# M451_v1 register map
File version: 1.0
Registers are 32-bit, read-write, reset 0x0 unless marked. A register's access mark holds for its fields unless they carry their own. Offsets are from the block's base; [hi:lo] are bit positions; {n}, {i} and the like mark numbered series.

## SYS — SYS Register Map
Base 0x40000000
0x00 SYS_PDID ro reset not defined — Part Device Identification Number Register
  [31:0] PDID — Part Device Identification Number (Read Only). This register reflects device part number code. Software can read this register to identify which device is used.
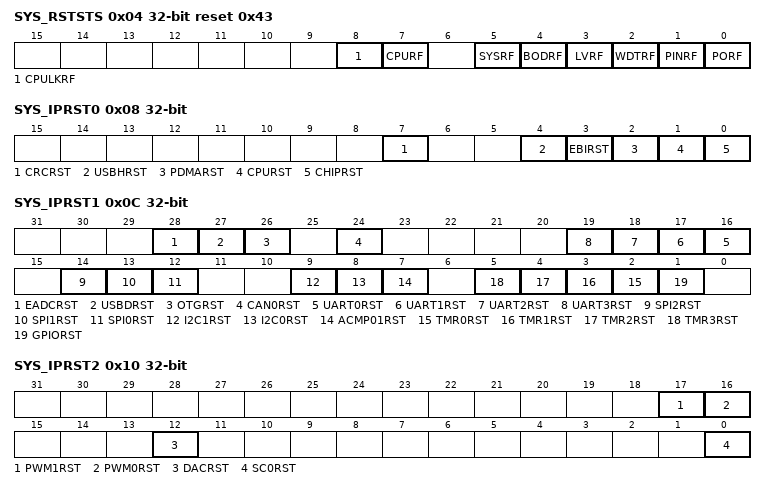
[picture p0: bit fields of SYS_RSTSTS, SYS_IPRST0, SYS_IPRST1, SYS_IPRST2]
0x04 SYS_RSTSTS reset 0x43 — System Reset Status Register
  [8] CPULKRF — the CPULK Reset Flag Is Set by Hardware If Cortex-m4 Lockup Happened (M45xD/M45xC Only). Note: Write 1 to clear this bit to 0.
    0=No reset from CPU lockup happened; 1=The Cortex-M4 lockup happened and chip is reset
  [7] CPURF — CPU Reset Flag. The CPU reset flag is set by hardware if software writes CPURST (SYS_IPRST0[1]) 1 to reset Cortex-M4 Core and Flash Memory Controller (FMC). Note: Write 1 to clear this bit to 0.
    0=No reset from CPU; 1=The Cortex-M4 Core and FMC are reset by software setting CPURST to 1
  [5] SYSRF — System Reset Flag. The system reset flag is set by the 'Reset Signal' from the Cortex-M4 Core to indicate the previous reset source. Note: Write 1 to clear this bit to 0.
    0=No reset from Cortex-M4; 1=The Cortex-M4 had issued the reset signal to reset the system by writing 1 to the bit SYSRESETREQ(AIRCR[2], Application Interrupt and Reset Control Register, address = 0xE000ED0C) in system control registers of Cortex-M4 core
  [4] BODRF — BOD Reset Flag. The BOD reset flag is set by the 'Reset Signal' from the Brown-Out Detector to indicate the previous reset source. Note: Write 1 to clear this bit to 0.
    0=No reset from BOD; 1=The BOD had issued the reset signal to reset the system
  [3] LVRF — LVR Reset Flag. The LVR reset flag is set by the 'Reset Signal' from the Low Voltage Reset Controller to indicate the previous reset source. Note: Write 1 to clear this bit to 0.
    0=No reset from LVR; 1=LVR controller had issued the reset signal to reset the system
  [2] WDTRF — WDT Reset Flag. The WDT reset flag is set by the 'Reset Signal' from the Watchdog Timer or Window Watchdog Timer to indicate the previous reset source. Note1: Write 1 to clear this bit to 0. Note2: Watchdog Timer register RSTF(WDT_CTL[2]) bit is set if the system has been reset by WDT time-out reset. Window Watchdog Timer register WWDTRF(WWDT_STATUS[1]) bit is set if the system has been reset by WWDT time-out reset.
    0=No reset from watchdog timer or window watchdog timer; 1=The watchdog timer or window watchdog timer had issued the reset signal to reset the system
  [1] PINRF — NRESET Pin Reset Flag. The nRESET pin reset flag is set by the 'Reset Signal' from the nRESET Pin to indicate the previous reset source. Note: Write 1 to clear this bit to 0.
    0=No reset from nRESET pin; 1=Pin nRESET had issued the reset signal to reset the system
  [0] PORF — POR Reset Flag. The POR reset flag is set by the 'Reset Signal' from the Power-on Reset (POR) Controller or bit CHIPRST (SYS_IPRST0[0]) to indicate the previous reset source. Note: Write 1 to clear this bit to 0.
    0=No reset from POR or CHIPRST; 1=Power-on Reset (POR) or CHIPRST had issued the reset signal to reset the system
0x08 SYS_IPRST0 — Peripheral Reset Control Register 0
  [7] CRCRST — CRC Calculation Controller Reset (Write Protect). Set this bit to 1 will generate a reset signal to the CRC calculation controller. User needs to set this bit to 0 to release from the reset state. Note: This bit is write protected. Refer to the SYS_REGLCTL register.
    0=CRC calculation controller normal operation; 1=CRC calculation controller reset
  [4] USBHRST — USBH Controller Reset (Write Protect) (M45xG/M45xE Only). Set this bit to 1 will generate a reset signal to the USB host controller. User needs to set this bit to 0 to release from the reset state. Note: This bit is write protected. Refer to the SYS_REGLCTL register.
    0=USBH controller normal operation; 1=USBH controller reset
  [3] EBIRST — EBI Controller Reset (Write Protect). Set this bit to 1 will generate a reset signal to the EBI. User needs to set this bit to 0 to release from the reset state. Note: This bit is write protected. Refer to the SYS_REGLCTL register.
    0=EBI controller normal operation; 1=EBI controller reset
  [2] PDMARST — PDMA Controller Reset (Write Protect). Setting this bit to 1 will generate a reset signal to the PDMA. User needs to set this bit to 0 to release from reset state. Note: This bit is write protected. Refer to the SYS_REGLCTL register.
    0=PDMA controller normal operation; 1=PDMA controller reset
  [1] CPURST — Processor Core One-shot Reset (Write Protect). Setting this bit will only reset the processor core and Flash Memory Controller(FMC), and this bit will automatically return to 0 after the 2 clock cycles. Note: This bit is write protected. Refer to the SYS_REGLCTL register.
    0=Processor core normal operation; 1=Processor core one-shot reset
  [0] CHIPRST — Chip One-shot Reset (Write Protect). Setting this bit will reset the whole chip, including Processor core and all peripherals, and this bit will automatically return to 0 after the 2 clock cycles. The CHIPRST is same as the POR reset, all the chip controllers is reset and the chip setting from flash are also reload. About the difference between CHIPRST and SYSRESETREQ(AIRCR[2]), please refer to section 6.2.2. Note: This bit is write protected. Refer to the SYS_REGLCTL register.
    0=Chip normal operation; 1=Chip one-shot reset
0x0C SYS_IPRST1 — Peripheral Reset Control Register 1
  [28] EADCRST — EADC Controller Reset
    0=EADC controller normal operation; 1=EADC controller reset
  [27] USBDRST — USB Device Controller Reset
    0=USB device controller normal operation; 1=USB device controller reset
  [26] OTGRST — OTG Controller Reset (M45xG/M45xE Only)
    0=OTG controller normal operation; 1=OTG controller reset
  [24] CAN0RST — CAN0 Controller Reset
    0=CAN0 controller normal operation; 1=CAN0 controller reset
  [n+16] UART{n}RST (n=0..3) — UART{n} Controller Reset
    0=UART{n} controller normal operation; 1=UART{n} controller reset
  [14] SPI2RST — SPI2 Controller Reset (M45xG/M45xE Only)
    0=SPI2 controller normal operation; 1=SPI2 controller reset
  [13] SPI1RST — SPI1 Controller Reset
    0=SPI1 controller normal operation; 1=SPI1 controller reset
  [12] SPI0RST — SPI0 Controller Reset
    0=SPI0 controller normal operation; 1=SPI0 controller reset
  [9] I2C1RST — I2C1 Controller Reset
    0=I2C1 controller normal operation; 1=I2C1 controller reset
  [8] I2C0RST — I2C0 Controller Reset
    0=I2C0 controller normal operation; 1=I2C0 controller reset
  [7] ACMP01RST — Analog Comparator 0/1 Controller Reset
    0=Analog Comparator 0/1 controller normal operation; 1=Analog Comparator 0/1 controller reset
  [n+2] TMR{n}RST (n=0..3) — Timer{n} Controller Reset
    0=Timer{n} controller normal operation; 1=Timer{n} controller reset
  [1] GPIORST — GPIO Controller Reset
    0=GPIO controller normal operation; 1=GPIO controller reset
0x10 SYS_IPRST2 — Peripheral Reset Control Register 2
  [17] PWM1RST — PWM1 Controller Reset
    0=PWM1 controller normal operation; 1=PWM1 controller reset
  [16] PWM0RST — PWM0 Controller Reset
    0=PWM0 controller normal operation; 1=PWM0 controller reset
  [12] DACRST — DAC Controller Reset
    0=DAC controller normal operation; 1=DAC controller reset
  [0] SC0RST — SC0 Controller Reset
    0=SC0 controller normal operation; 1=SC0 controller reset
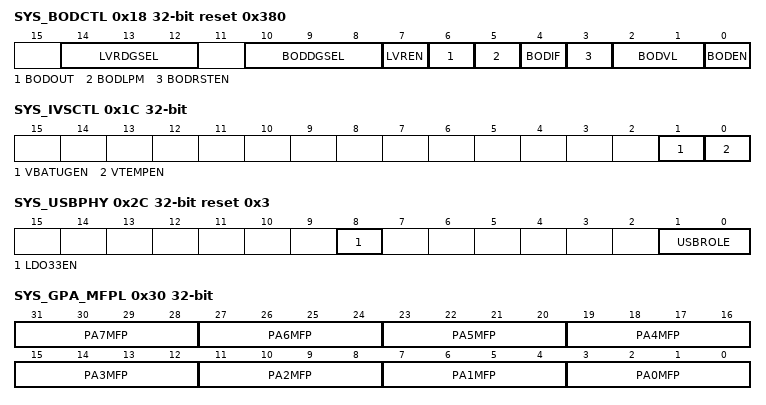
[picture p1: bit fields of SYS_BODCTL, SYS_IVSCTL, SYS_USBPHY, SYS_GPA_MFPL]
0x18 SYS_BODCTL reset 0x380 (reset mask 0xFFFFFFF0) — Brown-out Detector Control Register
  [14:12] LVRDGSEL — LVR Output De-glitch Time Select (Write Protect). Note: These bits are write protected. Refer to the SYS_REGLCTL register.
    0=Without de-glitch function; 1=4 system clock (HCLK); 2=8 system clock (HCLK); 3=16 system clock (HCLK); 4=32 system clock (HCLK); 5=64 system clock (HCLK); 6=128 system clock (HCLK); 7=256 system clock (HCLK)
  [10:8] BODDGSEL — Brown-out Detector Output De-glitch Time Select (Write Protect). Note: These bits are write protected. Refer to the SYS_REGLCTL register.
    0=BOD output is sampled by RC10K clock; 1=4 system clock (HCLK); 2=8 system clock (HCLK); 3=16 system clock (HCLK); 4=32 system clock (HCLK); 5=64 system clock (HCLK); 6=128 system clock (HCLK); 7=256 system clock (HCLK)
  [7] LVREN — Low Voltage Reset Enable Bit (Write Protect). The LVR function resets the chip when the input power voltage is lower than LVR circuit setting. LVR function is enabled by default. Note1: After enabling the bit, the LVR function will be active with 100us delay for LVR output stable (default). Note2: This bit is write protected. Refer to the SYS_REGLCTL register. Note3: LIRC must be enabled before enable LVR.
    0=Low Voltage Reset function Disabled; 1=Low Voltage Reset function Enabled
  [6] BODOUT — Brown-out Detector Output Status. It means the detected voltage is lower than BODVL setting. If the BODEN is 0, BOD function disabled , this bit always responds 0.
    0=Brown-out Detector output status is 0; 1=Brown-out Detector output status is 1
  [5] BODLPM — Brown-out Detector Low Power Mode (Write Protect). Note1: The BOD consumes about 100uA in normal mode, the low power mode can reduce the current to about 1/10 but slow the BOD response. Note2: This bit is write protected. Refer to the SYS_REGLCTL register.
    0=BOD operate in normal mode (default); 1=BOD Low Power mode Enabled
  [4] BODIF — Brown-out Detector Interrupt Flag. Note: Write 1 to clear this bit to 0.
    0=Brown-out Detector does not detect any voltage draft at VDD down through or up through the voltage of BODVL setting; 1=When Brown-out Detector detects the VDD is dropped down through the voltage of BODVL setting or the VDD is raised up through the voltage of BODVL setting, this bit is set to 1 and the brown-out interrupt is requested if brown-out interrupt is enabled
  [3] BODRSTEN — Brown-out Reset Enable Bit (Write Protect). The default value is set by flash controller user configuration register CBORST(CONFIG0[20]) bit . Note1: While the Brown-out Detector function is enabled (BODEN high) and BOD reset function is enabled (BODRSTEN high), BOD will assert a signal to reset chip when the detected voltage is lower than the threshold (BODOUT high). While the BOD function is enabled (BODEN high) and BOD interrupt function is enabled (BODRSTEN low), BOD will assert an interrupt if BODOUT is high. BOD interrupt will keep till to the BODEN set to 0. BOD interrupt can be blocked by disabling the NVIC BOD interrupt or disabling BOD function (set BODEN low). Note2: This bit is write protected. Refer to the SYS_REGLCTL register.
    0=Brown-out 'INTERRUPT' function Enabled; 1=Brown-out 'RESET' function Enabled
  [2:1] BODVL — Brown-out Detector Threshold Voltage Selection (Write Protect). The default value is set by flash controller user configuration register CBOV (CONFIG0 [22:21]). Note: This bit is write protected. Refer to the SYS_REGLCTL register.
    0=Brown-Out Detector threshold voltage is 2.2V; 1=Brown-Out Detector threshold voltage is 2.7V; 2=Brown-Out Detector threshold voltage is 3.7V; 3=Brown-Out Detector threshold voltage is 4.4V
  [0] BODEN — Brown-out Detector Enable Bit (Write Protect). The default value is set by flash controller user configuration register CBODEN (CONFIG0 [23]). Note1: This bit is write protected. Refer to the SYS_REGLCTL register. Note2: LIRC must be enabled before enable BOD.
    0=Brown-out Detector function Disabled; 1=Brown-out Detector function Enabled
0x1C SYS_IVSCTL — Internal Voltage Source Control Register
  [1] VBATUGEN — VBAT Unity Gain Buffer Enable Bit. This bit is used to enable/disable VBAT unity gain buffer function. Note: After this bit is set to 1, the value of VBAT unity gain buffer output voltage can be obtained from ADC conversion result
    0=VBAT unity gain buffer function Disabled (default); 1=VBAT unity gain buffer function Enabled
  [0] VTEMPEN — Temperature Sensor Enable Bit. This bit is used to enable/disable temperature sensor function. Note: After this bit is set to 1, the value of temperature sensor output can be obtained from ADC conversion result. Please refer to ADC function chapter for details.
    0=Temperature sensor function Disabled (default); 1=Temperature sensor function Enabled
0x24 SYS_PORCTL (reset mask 0xFFFF0000) — Power-On-reset Controller Register
  [15:0] POROFF — Power-on Reset Enable Bit (Write Protect). When powered on, the POR circuit generates a reset signal to reset the whole chip function, but noise on the power may cause the POR active again. User can disable internal POR circuit to avoid unpredictable noise to cause chip reset by writing 0x5AA5 to this field. The POR function will be active again when this field is set to another value or chip is reset by other reset source, including: nRESET, Watchdog, LVR reset, BOD reset, ICE reset command and the software-chip reset function. Note: This bit is write protected. Refer to the SYS_REGLCTL register.
0x28 SYS_VREFCTL — VREF Control Register
  [4:0] VREFCTL — VREF Control Bits (Write Protect). Note1: This bit is write protected. Refer to the SYS_REGLCTL register. Note2: Connecting a 1uF capacitor to AVSS will make internal reference voltage more stable.
    0=VREF is from external pin; 3=VREF is internal 2.56V; 7=VREF is internal 2.048V; 11=VREF is internal 3.072V; 15=VREF is internal 4.096V
0x2C SYS_USBPHY reset 0x3 — USB PHY Control Register (M45xG/M45xE Only)
  [8] LDO33EN — USB LDO33 Enable Bit (Write Protect) (M45xG/M45xE Only). Note: This bit is write protected. Refer to the SYS_REGLCTL register.
    0=USB LDO33 Disabled; 1=USB LDO33 Enabled
  [1:0] USBROLE — USB Role Option (Write Protect) (M45xG/M45xE Only). These two bits are used to select the role of USB. Note: This bit is write protected. Refer to the SYS_REGLCTL register.
    0=Standard USB Device mode; 1=Standard USB Host mode; 2=ID dependent mode; 3=On-The-Go device mode
0x30 SYS_GPA_MFPL — GPIOA Low Byte Multiple Function Control Register
  [31:28] PA7MFP — PA.7 Multi-function Pin Selection
  [27:24] PA6MFP — PA.6 Multi-function Pin Selection
  [23:20] PA5MFP — PA.5 Multi-function Pin Selection
  [19:16] PA4MFP — PA.4 Multi-function Pin Selection
  [15:12] PA3MFP — PA.3 Multi-function Pin Selection
  [11:8] PA2MFP — PA.2 Multi-function Pin Selection
  [7:4] PA1MFP — PA.1 Multi-function Pin Selection
  [3:0] PA0MFP — PA.0 Multi-function Pin Selection
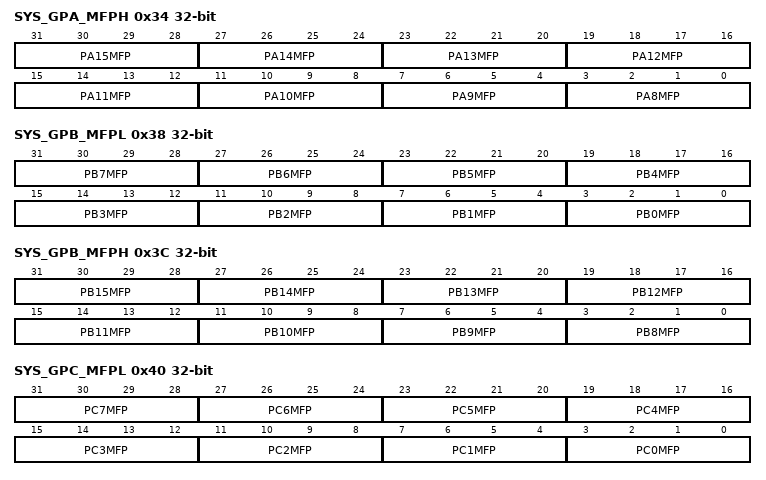
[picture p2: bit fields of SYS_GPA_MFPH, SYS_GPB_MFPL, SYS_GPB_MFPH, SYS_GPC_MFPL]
0x34 SYS_GPA_MFPH — GPIOA High Byte Multiple Function Control Register
  [31:28] PA15MFP — PA.15 Multi-function Pin Selection
  [27:24] PA14MFP — PA.14 Multi-function Pin Selection
  [23:20] PA13MFP — PA.13 Multi-function Pin Selection
  [19:16] PA12MFP — PA.12 Multi-function Pin Selection
  [15:12] PA11MFP — PA.11 Multi-function Pin Selection
  [11:8] PA10MFP — PA.10 Multi-function Pin Selection
  [7:4] PA9MFP — PA.9 Multi-function Pin Selection
  [3:0] PA8MFP — PA.8 Multi-function Pin Selection
0x38 SYS_GPB_MFPL — GPIOB Low Byte Multiple Function Control Register
  [31:28] PB7MFP — PB.7 Multi-function Pin Selection
  [27:24] PB6MFP — PB.6 Multi-function Pin Selection
  [23:20] PB5MFP — PB.5 Multi-function Pin Selection
  [19:16] PB4MFP — PB.4 Multi-function Pin Selection
  [15:12] PB3MFP — PB.3 Multi-function Pin Selection
  [11:8] PB2MFP — PB.2 Multi-function Pin Selection
  [7:4] PB1MFP — PB.1 Multi-function Pin Selection
  [3:0] PB0MFP — PB.0 Multi-function Pin Selection
0x3C SYS_GPB_MFPH — GPIOB High Byte Multiple Function Control Register
  [31:28] PB15MFP — PB.15 Multi-function Pin Selection
  [27:24] PB14MFP — PB.14 Multi-function Pin Selection
  [23:20] PB13MFP — PB.13 Multi-function Pin Selection
  [19:16] PB12MFP — PB.12 Multi-function Pin Selection
  [15:12] PB11MFP — PB.11 Multi-function Pin Selection
  [11:8] PB10MFP — PB.10 Multi-function Pin Selection
  [7:4] PB9MFP — PB.9 Multi-function Pin Selection
  [3:0] PB8MFP — PB.8 Multi-function Pin Selection
0x40 SYS_GPC_MFPL — GPIOC Low Byte Multiple Function Control Register
  [31:28] PC7MFP — PC.7 Multi-function Pin Selection
  [27:24] PC6MFP — PC.6 Multi-function Pin Selection
  [23:20] PC5MFP — PC.5 Multi-function Pin Selection
  [19:16] PC4MFP — PC.4 Multi-function Pin Selection
  [15:12] PC3MFP — PC.3 Multi-function Pin Selection
  [11:8] PC2MFP — PC.2 Multi-function Pin Selection
  [7:4] PC1MFP — PC.1 Multi-function Pin Selection
  [3:0] PC0MFP — PC.0 Multi-function Pin Selection
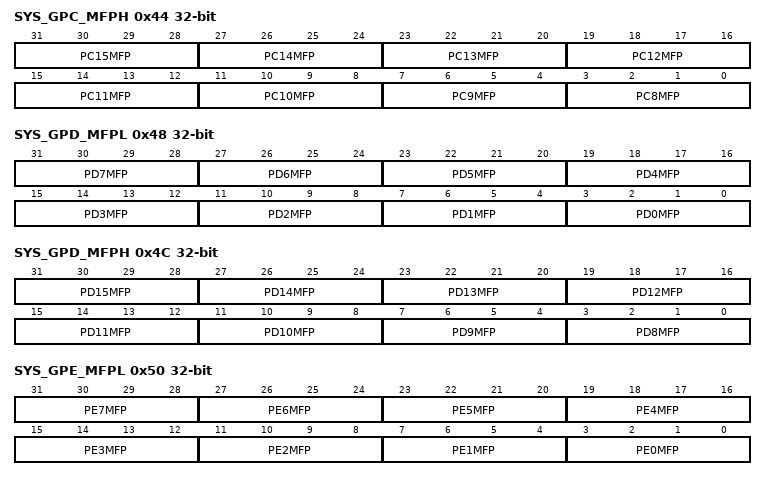
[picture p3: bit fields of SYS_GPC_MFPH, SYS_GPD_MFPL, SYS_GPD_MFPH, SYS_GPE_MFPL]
0x44 SYS_GPC_MFPH — GPIOC High Byte Multiple Function Control Register
  [31:28] PC15MFP — PC.15 Multi-function Pin Selection
  [27:24] PC14MFP — PC.14 Multi-function Pin Selection
  [23:20] PC13MFP — PC.13 Multi-function Pin Selection
  [19:16] PC12MFP — PC.12 Multi-function Pin Selection
  [15:12] PC11MFP — PC.11 Multi-function Pin Selection
  [11:8] PC10MFP — PC.10 Multi-function Pin Selection
  [7:4] PC9MFP — PC.9 Multi-function Pin Selection
  [3:0] PC8MFP — PC.8 Multi-function Pin Selection
0x48 SYS_GPD_MFPL — GPIOD Low Byte Multiple Function Control Register
  [31:28] PD7MFP — PD.7 Multi-function Pin Selection
  [27:24] PD6MFP — PD.6 Multi-function Pin Selection
  [23:20] PD5MFP — PD.5 Multi-function Pin Selection
  [19:16] PD4MFP — PD.4 Multi-function Pin Selection
  [15:12] PD3MFP — PD.3 Multi-function Pin Selection
  [11:8] PD2MFP — PD.2 Multi-function Pin Selection
  [7:4] PD1MFP — PD.1 Multi-function Pin Selection
  [3:0] PD0MFP — PD.0 Multi-function Pin Selection
0x4C SYS_GPD_MFPH — GPIOD High Byte Multiple Function Control Register
  [31:28] PD15MFP — PD.15 Multi-function Pin Selection
  [27:24] PD14MFP — PD.14 Multi-function Pin Selection
  [23:20] PD13MFP — PD.13 Multi-function Pin Selection
  [19:16] PD12MFP — PD.12 Multi-function Pin Selection
  [15:12] PD11MFP — PD.11 Multi-function Pin Selection
  [11:8] PD10MFP — PD.10 Multi-function Pin Selection
  [7:4] PD9MFP — PD.9 Multi-function Pin Selection
  [3:0] PD8MFP — PD.8 Multi-function Pin Selection
0x50 SYS_GPE_MFPL — GPIOE Low Byte Multiple Function Control Register
  [31:28] PE7MFP — PE.7 Multi-function Pin Selection
  [27:24] PE6MFP — PE.6 Multi-function Pin Selection
  [23:20] PE5MFP — PE.5 Multi-function Pin Selection
  [19:16] PE4MFP — PE.4 Multi-function Pin Selection
  [15:12] PE3MFP — PE.3 Multi-function Pin Selection
  [11:8] PE2MFP — PE.2 Multi-function Pin Selection
  [7:4] PE1MFP — PE.1 Multi-function Pin Selection
  [3:0] PE0MFP — PE.0 Multi-function Pin Selection
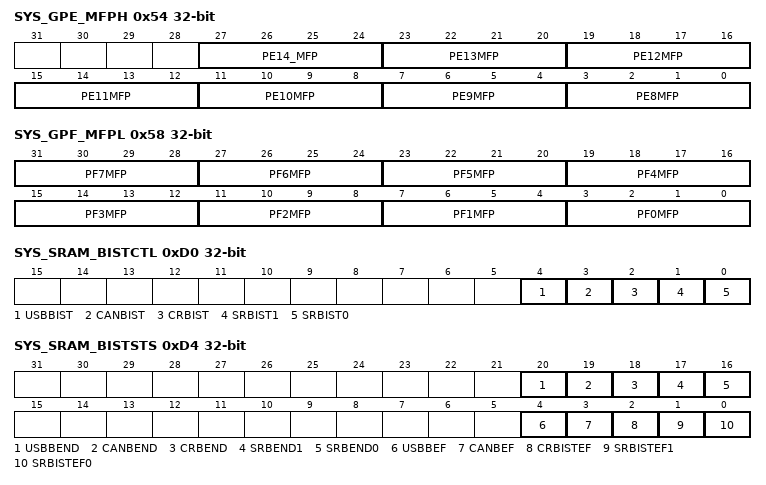
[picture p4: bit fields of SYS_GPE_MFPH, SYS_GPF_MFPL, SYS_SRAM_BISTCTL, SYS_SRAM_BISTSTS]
0x54 SYS_GPE_MFPH — GPIOE High Byte Multiple Function Control Register
  [27:24] PE14_MFP — PE.14 Multi-function Pin Selection
  [23:20] PE13MFP — PE.13 Multi-function Pin Selection
  [19:16] PE12MFP — PE.12 Multi-function Pin Selection
  [15:12] PE11MFP — PE.11 Multi-function Pin Selection
  [11:8] PE10MFP — PE.10 Multi-function Pin Selection
  [7:4] PE9MFP — PE.9 Multi-function Pin Selection
  [3:0] PE8MFP — PE.8 Multi-function Pin Selection
0x58 SYS_GPF_MFPL — GPIOF Low Byte Multiple Function Control Register
  [31:28] PF7MFP — PF.7 Multi-function Pin Selection
  [27:24] PF6MFP — PF.6 Multi-function Pin Selection
  [23:20] PF5MFP — PF.5 Multi-function Pin Selection
  [19:16] PF4MFP — PF.4 Multi-function Pin Selection
  [15:12] PF3MFP — PF.3 Multi-function Pin Selection
  [11:8] PF2MFP — PF.2 Multi-function Pin Selection
  [7:4] PF1MFP — PF.1 Multi-function Pin Selection
  [3:0] PF0MFP — PF.0 Multi-function Pin Selection
0xC0 SYS_SRAM_INTCTL — System SRAM Interrupt Enable Control Register
  [0] PERRIEN — SRAM Parity Check Error Interrupt Enable Bit
    0=SRAM parity check error interrupt Disabled; 1=SRAM parity check error interrupt Enabled
0xC4 SYS_SRAM_STATUS ro — System SRAM Parity Error Status Register
  [0] PERRIF — SRAM Parity Check Error Flag
    0=No System SRAM parity error; 1=System SRAM parity error occur
0xC8 SYS_SRAM_ERRADDR ro — System SRAM Parity Check Error Address Register
  [31:0] ERRADDR — System SRAM Parity Error Address. This register shows system SRAM parity error byte address.
0xD0 SYS_SRAM_BISTCTL — System SRAM BIST Test Control Register
  [4] USBBIST — USB BIST Enable Bit (Write Protect). This bit enables BIST test for USB RAM. Note: This bit is write protected. Refer to the SYS_REGLCTL register.
    0=system USB BIST Disabled; 1=system USB BIST Enabled
  [3] CANBIST — CAN BIST Enable Bit (Write Protect). This bit enables BIST test for CAN RAM. Note: This bit is write protected. Refer to the SYS_REGLCTL register.
    0=system CAN BIST Disabled; 1=system CAN BIST Enabled
  [2] CRBIST — CACHE BIST Enable Bit (Write Protect). This bit enables BIST test for CACHE RAM. Note: This bit is write protected. Refer to the SYS_REGLCTL register.
    0=system CACHE BIST Disabled; 1=system CACHE BIST Enabled
  [1] SRBIST1 — 2nd SRAM BIST Enable Bit (Write Protect). This bit enables BIST test for SRAM located in address 0x2000_4000 ~0x2000_7FFF. Note: This bit is write protected. Refer to the SYS_REGLCTL register.
    0=system SRAM BIST Disabled; 1=system SRAM BIST Enabled
  [0] SRBIST0 — 1st SRAM BIST Enable Bit (Write Protect). This bit enables BIST test for SRAM located in address 0x2000_0000 ~0x2000_3FFF. Note: This bit is write protected. Refer to the SYS_REGLCTL register.
    0=system SRAM BIST Disabled; 1=system SRAM BIST Enabled
0xD4 SYS_SRAM_BISTSTS ro (reset mask 0xFF00FF00) — System SRAM BIST Test Status Register
  [20] USBBEND — USB SRAM BIST Test Finish
    0=USB SRAM BIST is active; 1=USB SRAM BIST test finish
  [19] CANBEND — CAN SRAM BIST Test Finish
    0=CAN SRAM BIST is active; 1=CAN SRAM BIST test finish
  [18] CRBEND — CACHE SRAM BIST Test Finish
    0=System CACHE RAM BIST is active; 1=System CACHE RAM BIST test finish
  [17] SRBEND1 — 2nd SRAM BIST Test Finish
    0=2nd system SRAM BIST is active; 1=2nd system SRAM BIST finish
  [16] SRBEND0 — 1st SRAM BIST Test Finish
    0=1st system SRAM BIST active; 1=1st system SRAM BIST finish
  [4] USBBEF — USB SRAM BIST Fail Flag
    0=USB SRAM BIST test pass; 1=USB SRAM BIST test fail
  [3] CANBEF — CAN SRAM BIST Fail Flag
    0=CAN SRAM BIST test pass; 1=CAN SRAM BIST test fail
  [2] CRBISTEF — CACHE SRAM BIST Fail Flag
    0=System CACHE RAM BIST test pass; 1=System CACHE RAM BIST test fail
  [1] SRBISTEF1 — 2nd System SRAM BIST Fail Flag
    0=2nd system SRAM BIST test pass; 1=2nd system SRAM BIST test fail
  [0] SRBISTEF0 — 1st System SRAM BIST Fail Flag
    0=1st system SRAM BIST test pass; 1=1st system SRAM BIST test fail
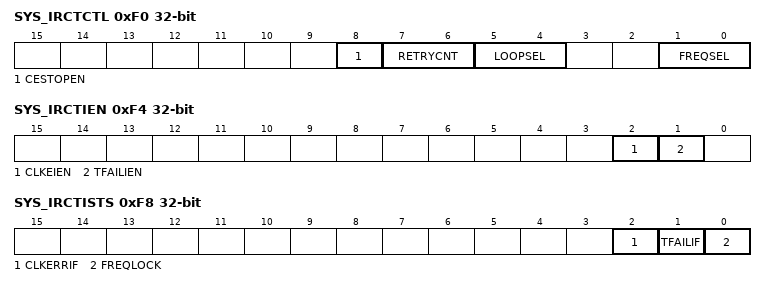
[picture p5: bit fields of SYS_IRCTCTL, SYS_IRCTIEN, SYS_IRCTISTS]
0xF0 SYS_IRCTCTL — HIRC Trim Control Register
  [8] CESTOPEN — Clock Error Stop Enable Bit
    0=The trim operation is keep going if clock is inaccuracy; 1=The trim operation is stopped if clock is inaccuracy
  [7:6] RETRYCNT — Trim Value Update Limitation Count. This field defines that how many times the auto trim circuit will try to update the HIRC trim value before the frequency of HIRC locked. Once the HIRC locked, the internal trim value update counter will be reset. If the trim value update counter reached this limitation value and frequency of HIRC still doesn't lock, the auto trim operation will be disabled and FREQSEL will be cleared to 00.
    0=Trim retry count limitation is 64 loops; 1=Trim retry count limitation is 128 loops; 2=Trim retry count limitation is 256 loops; 3=Trim retry count limitation is 512 loops
  [5:4] LOOPSEL — Trim Calculation Loop Selection. This field defines that trim value calculation is based on how many 32.768 kHz clock. Note: For example, if LOOPSEL is set as 00, auto trim circuit will calculate trim value based on the average frequency difference in 4 32.768 kHz clock.
    0=Trim value calculation is based on average difference in 4 32.768 kHz clock; 1=Trim value calculation is based on average difference in 8 32.768 kHz clock; 2=Trim value calculation is based on average difference in 16 32.768 kHz clock; 3=Trim value calculation is based on average difference in 32 32.768 kHz clock
  [1:0] FREQSEL — Trim Frequency Selection. This field indicates the target frequency of 22.1184 MHz internal high speed RC oscillator (HIRC) auto trim. During auto trim operation, if clock error detected with CESTOPEN is set to 1 or trim retry limitation count reached, this field will be cleared to 00 automatically. Note: HIRC auto trim cannot work normally at power down mode. These bits must be cleared before entering power down mode.
    0=Disable HIRC auto trim function; 1=Enable HIRC auto trim function and trim HIRC to 22.1184 MHz
0xF4 SYS_IRCTIEN — HIRC Trim Interrupt Enable Register
  [2] CLKEIEN — Clock Error Interrupt Enable Bit. This bit controls if CPU would get an interrupt while clock is inaccuracy during auto trim operation. If this bit is set to1, and CLKERRIF(SYS_IRCTSTS[2]) is set during auto trim operation, an interrupt will be triggered to notify the clock frequency is inaccuracy.
    0=Disable CLKERRIF(SYS_IRCTSTS[2]) status to trigger an interrupt to CPU; 1=Enable CLKERRIF(SYS_IRCTSTS[2]) status to trigger an interrupt to CPU
  [1] TFAILIEN — Trim Failure Interrupt Enable Bit. This bit controls if an interrupt will be triggered while HIRC trim value update limitation count reached and HIRC frequency still not locked on target frequency set by FREQSEL(SYS_IRCTCTL[1:0]). If this bit is high and TFAILIF(SYS_IRCTSTS[1]) is set during auto trim operation, an interrupt will be triggered to notify that HIRC trim value update limitation count was reached.
    0=Disable TFAILIF(SYS_IRCTSTS[1]) status to trigger an interrupt to CPU; 1=Enable TFAILIF(SYS_IRCTSTS[1]) status to trigger an interrupt to CPU
0xF8 SYS_IRCTISTS — HIRC Trim Interrupt Status Register
  [2] CLKERRIF — Clock Error Interrupt Status. When the frequency of 32.768 kHz external low speed crystal oscillator (LXT) or 22.1184 MHz internal high speed RC oscillator (HIRC) is shift larger to unreasonable value, this bit will be set and to be an indicate that clock frequency is inaccuracy. Once this bit is set to 1, the auto trim operation stopped and FREQSEL(SYS_IRCTCL[1:0]) will be cleared to 00 by hardware automatically if CESTOPEN(SYS_IRCTCTL[8]) is set to 1. If this bit is set and CLKEIEN(SYS_IRCTIEN[2]) is high, an interrupt will be triggered to notify the clock frequency is inaccuracy. Write 1 to clear this to 0.
    0=Clock frequency is accuracy; 1=Clock frequency is inaccuracy
  [1] TFAILIF — Trim Failure Interrupt Status. This bit indicates that HIRC trim value update limitation count reached and the HIRC clock frequency still doesn't be locked. Once this bit is set, the auto trim operation stopped and FREQSEL(SYS_iRCTCTL[1:0]) will be cleared to 00 by hardware automatically. If this bit is set and TFAILIEN(SYS_IRCTIEN[1]) is high, an interrupt will be triggered to notify that HIRC trim value update limitation count was reached. Write 1 to clear this to 0.
    0=Trim value update limitation count does not reach; 1=Trim value update limitation count reached and HIRC frequency still not locked
  [0] FREQLOCK — HIRC Frequency Lock Status. This bit indicates the HIRC frequency is locked. This is a status bit and doesn't trigger any interrupt.
    0=The internal high-speed oscillator frequency doesn't lock at 22.1184 MHz yet; 1=The internal high-speed oscillator frequency locked at 22.1184 MHz
0x100 SYS_REGLCTL — Register Lock Control Register
  [7:0] REGLCTL — Register Lock Control Code (Write Only). Some registers have write-protection function. Writing these registers have to disable the protected function by writing the sequence value '59h', '16h', '88h' to this field. After this sequence is completed, the REGLCTL bit will be set to 1 and write-protection registers can be normal write. Register Lock Control Disable Index (Read Only). The Protected registers are: SYS_IPRST0: address 0x4000_0008. SYS_BODCTL: address 0x4000_0018. SYS_PORCTL: address 0x4000_0024. SYS_VREFCTL: address 0x4000_0028. SYS_USBPHY: address 0x4000_002C. CLK_PWRCTL: address 0x4000_0200 (bit[6] is not protected for power-down wake-up interrupt clear). SYS_SRAM_BISTCTL: address 0x4000_00D0. CLK_APBCLK0 [0]: address 0x4000_0208 (bit[0] is watchdog clock enable). CLK_CLKSEL0: address 0x4000_0210 (for HCLK and CPU STCLK clock source select). CLK_CLKSEL1 [1:0]: address 0x4000_0214 (for watchdog clock source select). CLK_CLKSEL1 [31:30]: address 0x4000_0214 (for window watchdog clock source select). CLK_CLKDSTS: address 0x4000_0274. NMIEN: address 0x4000_0300. FMC_ISPCTL: address 0x4000_C000 (Flash ISP Control register). FMC_ISPTRG: address 0x4000_C010 (ISP Trigger Control register). FMC_ISPSTS: address 0x4000_C040. WDT_CTL: address 0x4004_0000. FMC_FTCTL: address 0x4000_5018. SYS_AHBMCTL: address 0x40000400. CLK_PLLCTL: address 0x40000240. PWM_CTL0: address 0x4005_8000. PWM_CTL0: address 0x4005_9000. PWM_DTCTL0_1: address 0x4005_8070. PWM_DTCTL0_1: address 0x4005_9070. PWM_DTCTL2_3: address 0x4005_8074. PWM_DTCTL2_3: address 0x4005_9074. PWM_DTCTL4_5: address 0x4005_8078. PWM_DTCTL4_5: address 0x4005_9078. PWM_BRKCTL0_1: address 0x4005_80C8. PWM_BRKCTL0_1: address 0x4005_90C8. PWM_BRKCTL2_3: address 0x4005_80CC. PWM_BRKCTL2_3: address 0x4005_90CC. PWM_BRKCTL4_5: address 0x4005_80D0. PWM_BRKCTL4_5: address 0x4005_90D0. PWM_INTEN1: address 0x4005_80E4. PWM_INTEN1: address 0x4005_90E4. PWM_INTSTS1: address 0x4005_80EC. PWM_INTSTS1: address 0x4005_90EC
    0=Write-protection Enabled for writing protected registers. Any write to the protected register is ignored; 1=Write-protection Disabled for writing protected registers
0x400 SYS_AHBMCTL reset 0x1 — AHB Bus Matrix Priority Control Register
  [0] INTACTEN — Highest AHB Bus Priority of Cortex M4 Core Enable Bit (Write Protect). Enable Cortex-M4 Core With Highest AHB Bus Priority In AHB Bus Matrix. Note: This bit is write protected. Refer to the SYS_REGLCTL register.
    0=Run robin mode; 1=Cortex-M4 CPU with highest bus priority when interrupt occusr
